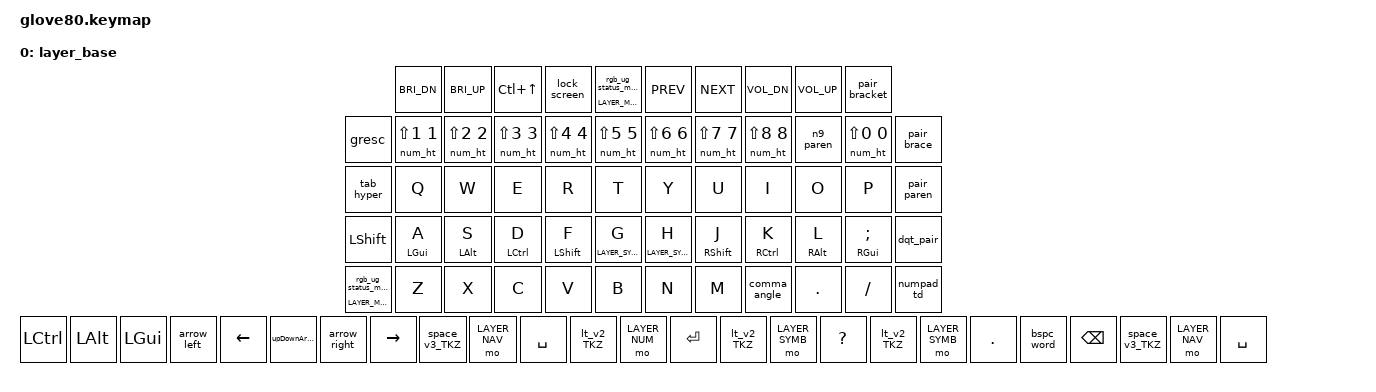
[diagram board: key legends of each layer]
/*
 * Copyright (c) 2020 The ZMK Contributors
 * SPDX-License-Identifier: MIT
 * 
 * Glove80 keymap adapted from sliceMK ErgoDox configuration
 * https://github.com/nothingfortune/unified-zmk-config-template-sliceMK
 */

#include <behaviors.dtsi>
#include <dt-bindings/zmk/keys.h>
#include <dt-bindings/zmk/bt.h>
#include <dt-bindings/zmk/ext_power.h>
#include <dt-bindings/zmk/outputs.h>
#include <dt-bindings/zmk/rgb.h>

/* Mouse speed MUST be defined BEFORE including pointing.h */
#define ZMK_POINTING_DEFAULT_MOVE_VAL 1500  /* default: 600 */
#define ZMK_POINTING_DEFAULT_SCRL_VAL 20    /* default: 10 */

#include <dt-bindings/zmk/pointing.h>

/* Layer definitions */
#define LAYER_BASE 0
#define LAYER_SYMB 1
#define LAYER_PWR 2
#define LAYER_NAV 3
#define LAYER_NMPAD 4
#define LAYER_FN 5
#define LAYER_MAGIC 6

/* Hyper key: Cmd+Ctrl+Alt+Shift - for app launchers like Raycast/Alfred */
#define HYPER LC(LS(LA(LGUI)))

/* Meh key: Ctrl+Alt+Shift (no Cmd) */
#define MEH LC(LS(LALT))

/* Mouse cursor settings - high speed, no acceleration ramp */
&mmv {
    delay-ms = <0>;
    time-to-max-speed-ms = <200>;
    acceleration-exponent = <2>;
};

/* Scroll wheel settings - instant max speed */
&msc {
    delay-ms = <0>;
    time-to-max-speed-ms = <0>;
    acceleration-exponent = <1>;
};

/ {
    behaviors {
        /* Grave/Escape key - Grave when held with Shift/Cmd, Escape otherwise */
        gresc: grave_escape {
            compatible = "zmk,behavior-mod-morph";
            #binding-cells = <0>;
            bindings = <&kp ESC>, <&kp GRAVE>;
            mods = <(MOD_LGUI|MOD_LSFT|MOD_RGUI|MOD_RSFT)>;
        };
        /* N9 key - outputs 9 normally, pair_paren macro when any modifier is held */
        n9_paren: n9_parentheses {
            compatible = "zmk,behavior-mod-morph";
            #binding-cells = <0>;
            bindings = <&kp N9>, <&pair_paren>;
            mods = <(MOD_LSFT|MOD_RSFT|MOD_LCTL|MOD_RCTL|MOD_LALT|MOD_RALT|MOD_LGUI|MOD_RGUI)>;
        };
        /* Comma key - outputs comma normally, pair_angle (<>) when any modifier is held */
        comma_angle: comma_angle_brackets {
            compatible = "zmk,behavior-mod-morph";
            #binding-cells = <0>;
            bindings = <&kp COMMA>, <&pair_angle>;
            mods = <(MOD_LSFT|MOD_RSFT|MOD_LCTL|MOD_RCTL|MOD_LALT|MOD_RALT|MOD_LGUI|MOD_RGUI)>;
        };
        /* Double quote key - outputs " normally, pair_dquote ("") when any modifier is held */
        dqt_pair: double_quote_pair {
            compatible = "zmk,behavior-mod-morph";
            #binding-cells = <0>;
            bindings = <&kp DQT>, <&pair_dquote>;
            mods = <(MOD_LSFT|MOD_RSFT|MOD_LCTL|MOD_RCTL|MOD_LALT|MOD_RALT|MOD_LGUI|MOD_RGUI)>;
        };
        /* Up/Down arrows mod-morph */
        upDownArrows: up_down_arrows {
            compatible = "zmk,behavior-mod-morph";
            #binding-cells = <0>;
            bindings = <&kp DOWN>, <&kp UP>;
            mods = <(MOD_LSFT|MOD_RSFT|MOD_LCTL|MOD_RCTL|MOD_LALT|MOD_RALT|MOD_LGUI|MOD_RGUI)>;
        };

        /* Layer tap for power layer */
        lt_pwr: layer_tap_pwr {
            compatible = "zmk,behavior-hold-tap";
            #binding-cells = <2>;
            flavor = "balanced";
            tapping-term-ms = <280>;
            quick-tap-ms = <175>;
            bindings = <&mo>, <&kp>;
        };

        /* Home row mods - tailored timings from go60 */
        hm: homerow_mod {
            compatible = "zmk,behavior-hold-tap";
            #binding-cells = <2>;
            flavor = "tap-preferred";
            tapping-term-ms = <160>;
            quick-tap-ms = <175>;
            require-prior-idle-ms = <125>;
            bindings = <&kp>, <&kp>;
        };

        /* Home row mods for shift - tailored timings from go60 */
        hms: homerow_mod_shift {
            compatible = "zmk,behavior-hold-tap";
            #binding-cells = <2>;
            flavor = "tap-preferred";
            tapping-term-ms = <160>;
            quick-tap-ms = <175>;
            require-prior-idle-ms = <125>;
            bindings = <&kp>, <&kp>;
        };

        /* Hold backspace = delete word (Option+Backspace on macOS) */
        bspc_word: backspace_word {
            compatible = "zmk,behavior-hold-tap";
            #binding-cells = <2>;
            flavor = "balanced";
            tapping-term-ms = <250>;
            quick-tap-ms = <0>;
            bindings = <&kp>, <&kp>;
        };

        /* Arrow keys with word jump on hold */
        arrow_left: arrow_word_left {
            compatible = "zmk,behavior-hold-tap";
            #binding-cells = <2>;
            flavor = "balanced";
            tapping-term-ms = <200>;
            quick-tap-ms = <150>;
            bindings = <&kp>, <&kp>;
        };

        arrow_right: arrow_word_right {
            compatible = "zmk,behavior-hold-tap";
            #binding-cells = <2>;
            flavor = "balanced";
            tapping-term-ms = <200>;
            quick-tap-ms = <150>;
            bindings = <&kp>, <&kp>;
        };

        /* Magic layer hold-tap for RGB status */
        magic: magic_hold_tap {
            compatible = "zmk,behavior-hold-tap";
            #binding-cells = <2>;
            flavor = "tap-preferred";
            tapping-term-ms = <200>;
            bindings = <&mo>, <&rgb_ug_status_macro>;
        };
    };

    macros {
        rgb_ug_status_macro: rgb_ug_status_macro_0 {
            compatible = "zmk,behavior-macro";
            #binding-cells = <0>;
            bindings = <&rgb_ug RGB_STATUS>;
        };

        bt_0: bt_profile_macro_0 {
            compatible = "zmk,behavior-macro";
            #binding-cells = <0>;
            bindings = <&out OUT_BLE>, <&bt BT_SEL 0>;
        };

        bt_1: bt_profile_macro_1 {
            compatible = "zmk,behavior-macro";
            #binding-cells = <0>;
            bindings = <&out OUT_BLE>, <&bt BT_SEL 1>;
        };

        bt_2: bt_profile_macro_2 {
            compatible = "zmk,behavior-macro";
            #binding-cells = <0>;
            bindings = <&out OUT_BLE>, <&bt BT_SEL 2>;
        };

        bt_3: bt_profile_macro_3 {
            compatible = "zmk,behavior-macro";
            #binding-cells = <0>;
            bindings = <&out OUT_BLE>, <&bt BT_SEL 3>;
        };

        /* Screenshot - ⌘⇧4 (selection) */
        screenshot: screenshot_macro {
            compatible = "zmk,behavior-macro";
            #binding-cells = <0>;
            bindings = <&kp LG(LS(N4))>;
        };

        /* Lock screen - ⌃⌘Q (macOS) */
        lock_screen: lock_screen_macro {
            compatible = "zmk,behavior-macro";
            #binding-cells = <0>;
            bindings = <&kp LC(LG(Q))>;
        };

        /* Screenshot to clipboard - ⌘⌃⇧4 */
        screenshot_clip: screenshot_clipboard_macro {
            compatible = "zmk,behavior-macro";
            #binding-cells = <0>;
            bindings = <&kp LG(LC(LS(N4)))>;
        };

        /* Rectangle: Left Half - ⌃⌥← */
        rect_left: rectangle_left_half {
            compatible = "zmk,behavior-macro";
            #binding-cells = <0>;
            bindings = <&kp LC(LA(LEFT))>;
        };

        /* Rectangle: Right Half - ⌃⌥→ */
        rect_right: rectangle_right_half {
            compatible = "zmk,behavior-macro";
            #binding-cells = <0>;
            bindings = <&kp LC(LA(RIGHT))>;
        };

        /* Rectangle: Maximize - ⌃⌥↩ */
        rect_max: rectangle_maximize {
            compatible = "zmk,behavior-macro";
            #binding-cells = <0>;
            bindings = <&kp LC(LA(RET))>;
        };

        /* Rectangle: Top Half - ⌃⌥↑ */
        rect_top: rectangle_top_half {
            compatible = "zmk,behavior-macro";
            #binding-cells = <0>;
            bindings = <&kp LC(LA(UP))>;
        };

        /* Rectangle: Bottom Half - ⌃⌥↓ */
        rect_bottom: rectangle_bottom_half {
            compatible = "zmk,behavior-macro";
            #binding-cells = <0>;
            bindings = <&kp LC(LA(DOWN))>;
        };

        /* Hyper key macro - ⌘⌃⌥⇧ for Raycast/Alfred */
        hyper_key: hyper_key_macro {
            compatible = "zmk,behavior-macro";
            #binding-cells = <0>;
            bindings = <&sk LGUI>, <&sk LALT>, <&sk LCTRL>, <&sk LSHFT>;
        };
        
        /* Auto-pair macros - type opening + closing, cursor moves to middle */
        pair_paren: pair_parentheses {
            compatible = "zmk,behavior-macro";
            #binding-cells = <0>;
            bindings = <&kp LPAR>, <&kp RPAR>, <&kp LEFT>;
        };

        pair_bracket: pair_brackets {
            compatible = "zmk,behavior-macro";
            #binding-cells = <0>;
            bindings = <&kp LBKT>, <&kp RBKT>, <&kp LEFT>;
        };

        pair_brace: pair_braces {
            compatible = "zmk,behavior-macro";
            #binding-cells = <0>;
            bindings = <&kp LBRC>, <&kp RBRC>, <&kp LEFT>;
        };

        pair_angle: pair_angle_brackets {
            compatible = "zmk,behavior-macro";
            #binding-cells = <0>;
            bindings = <&kp LT>, <&kp GT>, <&kp LEFT>;
        };

        pair_dquote: pair_double_quotes {
            compatible = "zmk,behavior-macro";
            #binding-cells = <0>;
            bindings = <&kp DQT>, <&kp DQT>, <&kp LEFT>;
        };

        pair_squote: pair_single_quotes {
            compatible = "zmk,behavior-macro";
            #binding-cells = <0>;
            bindings = <&kp SQT>, <&kp SQT>, <&kp LEFT>;
        };

        pair_backtick: pair_backticks {
            compatible = "zmk,behavior-macro";
            #binding-cells = <0>;
            bindings = <&kp GRAVE>, <&kp GRAVE>, <&kp LEFT>;
        };

    };

    keymap {
        compatible = "zmk,keymap";

        /* LAYER 0: Base Layer - QWERTY with Home Row Mods (matched to go60 as close as possible) */
        layer_base {
            bindings = <
            /* Row 0: Function row */
            &kp C_BRI_DN &kp C_BRI_UP &kp LC(UP) &lock_screen &magic LAYER_MAGIC 0 &kp C_PREV &kp C_NEXT &kp C_VOL_DN &kp C_VOL_UP &pair_bracket
            /* Row 1: Number row */
            &gresc &num_ht LS(N1) N1 &num_ht LS(N2) N2 &num_ht LS(N3) N3 &num_ht LS(N4) N4 &num_ht LS(N5) N5 &num_ht LS(N6) N6 &num_ht LS(N7) N7 &num_ht LS(N8) N8 &n9_paren &num_ht LS(N0) N0 &pair_brace
            /* Row 2: Top alpha row */
            &tab_hyper &kp Q &kp W &kp E &kp R &kp T &kp Y &kp U &kp I &kp O &kp P &pair_paren
            /* Row 3: Home row with mods */
            &kp LSHFT &hm LGUI A &hm LALT S &hm LCTRL D &hms LSHFT F &lt LAYER_SYMB G &lt LAYER_SYMB H &hms RSHFT J &hm RCTRL K &hm RALT L &hm RGUI SEMI &dqt_pair
            /* Row 4: Bottom alpha + inner keys */
            &magic LAYER_MAGIC 0 &kp Z &kp X &kp C &kp V &kp B &kp N &kp M &comma_angle &kp DOT &kp FSLH &numpad_td
            /* Row 5: Thumb cluster */
            &kp LCTRL &kp LALT &kp LGUI &arrow_left &kp LEFT &upDownArrows &arrow_right &kp RIGHT &space_v3_TKZ &mo LAYER_NAV &kp SPACE &lt_v2_TKZ &mo LAYER_NUM &kp RET &lt_v2_TKZ &mo LAYER_SYMB &kp QMARK &lt_v2_TKZ &mo LAYER_SYMB &kp PERIOD &bspc_word &kp BSPC &space_v3_TKZ &mo LAYER_NAV &kp SPACE
            >;
        }
        };

        /* LAYER 1: Symbol Layer - matches sliceMK ErgoDox layout */
        layer_symb {
            bindings = <
            /* Row 0: Function row */
            &none               &none        &none        &none        &none                                                                                                       &none        &none        &none        &none           &trans
            /* Row 1: ~ on left, ` and trans on right */
            &none               &none    &none        &none        &none        &none                                                                               &none      &none        &none        &none        &none       &trans
            /* Row 2: _ $ # ^ on left (QWER), _ @ % on right (UIO) */
            &none               &kp TILDE        &kp DLLR     &kp HASH     &kp CARET    &none                                                                               &none      &kp UNDER    &kp AT       &kp PRCNT    &kp GRAVE           &trans
            /* Row 3: - * | & on left (ASDF), ( ) + = : on right (JKL;') */
            &none               &kp MINUS    &kp ASTRK    &kp PIPE     &kp AMPS     &none                                                                               &none      &pair_paren     &kp RPAR     &kp PLUS     &kp EQUAL       &kp COLON
            /* Row 4: { } < > on left (ZXCV), [ ] ! ? on right (M,./) */
            &none               &pair_brace     &kp RBRC     &kp LT       &kp GT       &none      &none        &none        &none         &none         &none         &none          &none      &pair_bracket     &kp RBKT     &kp EXCL     &kp QMARK       &trans
            /* Row 5: Thumb cluster - transparent */
            &trans              &trans       &trans       &trans       &trans                 &trans       &trans       &none         &none         &trans        &trans                    &trans       &trans       &trans       &trans          &none
            >;
        };

        /* LAYER 2: Power/Shortcuts Layer */
        layer_pwr {
            bindings = <
            &none               &none        &none        &none        &none                                                                                                       &none        &none        &none        &none           &none
            &none               &kp LC(Z)    &kp LC(LS(Z)) &kp LC(LS(N4)) &none     &none                                                                               &none      &none        &none        &none        &none           &kp LC(BSPC)
            &none               &kp LC(A)    &kp LS(TAB)  &kp TAB      &none        &none                                                                               &none      &kp LC(LEFT) &kp UP       &kp LC(RIGHT) &kp PG_UP      &kp LC(DEL)
            &none               &sk LCTRL    &sk LSHFT    &sk LALT     &sk LGUI     &sk LC(LS(LA(LGUI)))                                                                &none      &kp LEFT     &kp DOWN     &kp RIGHT    &kp PG_DN       &none
            &none               &kp LC(X)    &kp LC(C)    &kp LC(V)    &none        &none      &none        &none        &none         &none         &none         &none          &none      &kp HOME     &none        &kp END      &none           &none
            &none               &none        &none        &trans       &trans                 &none        &none        &none         &none         &none         &none                     &kp LS(LA(LEFT)) &trans   &trans       &kp LS(LA(RIGHT)) &none
            >;
        };

        /* LAYER 3: Navigation/Mouse Layer */
        layer_nav {
            bindings = <
            &none               &none        &none        &none        &none                                                                                                       &none        &none        &none        &none           &none
            &none               &none        &msc SCRL_UP &none        &mkp RCLK    &none                                                                               &none      &mkp RCLK    &none        &msc SCRL_UP &none           &none
            &none               &none        &msc SCRL_DOWN &mmv MOVE_UP &mkp LCLK  &none                                                                               &none      &mkp LCLK    &mmv MOVE_UP &msc SCRL_DOWN &none        &none
            &none               &none        &mmv MOVE_LEFT &mmv MOVE_DOWN &mmv MOVE_RIGHT &none                                                                        &none      &mmv MOVE_LEFT &mmv MOVE_DOWN &mmv MOVE_RIGHT &none   &none
            &none               &none        &none        &none        &none        &none      &none        &none        &none         &none         &none         &none          &none      &none        &none        &none        &none           &none
            &none               &none        &none        &mkp LCLK    &mkp RCLK              &none        &none        &none         &none         &none         &none                     &trans       &trans       &trans       &trans          &none
            >;
        };

        /* LAYER 4: Numpad Layer */
        layer_nmpad {
            bindings = <
            &none               &kp F1       &kp F2       &kp F3       &kp F4                                                                                                      &kp F7       &kp F8       &kp F9       &kp F10         &none
            &none               &kp F5       &kp F6       &none        &none        &none                                                                               &none      &kp F11      &kp F12      &none        &none           &trans
            &kp TAB             &kp FSLH     &kp N7       &kp N8       &kp N9       &kp ASTRK                                                                           &none      &kp FSLH     &kp N7       &kp N8       &kp N9          &kp ASTRK
            &none               &kp MINUS    &kp N4       &kp N5       &kp N6       &kp PLUS                                                                            &none      &kp MINUS    &kp N4       &kp N5       &kp N6          &kp PLUS
            &none               &none        &kp N1       &kp N2       &kp N3       &kp EQUAL  &kp C_BRI_DN &kp C_BRI_UP &none         &none         &none         &none          &none      &none        &kp N1       &kp N2       &kp N3          &kp EQUAL
            &none               &none        &kp DOT      &kp N0       &kp COMMA              &none        &none        &none         &none         &none         &none                     &kp DOT      &kp N0       &kp COMMA    &none           &trans
            >;
        };

        /* LAYER 5: Function/System Layer */
        layer_fn {
            bindings = <
            &bt BT_SEL 0        &bt BT_SEL 1 &bt BT_SEL 2 &bt BT_SEL 3 &bt BT_SEL 4                                                                                                &none        &none        &none        &none           &bt BT_CLR
            &out OUT_USB        &kp F1       &kp F2       &kp F3       &kp F4       &none                                                                               &none      &kp F13      &kp F14      &kp F15      &kp F16         &none
            &out OUT_BLE        &kp F5       &kp F6       &kp F7       &kp F8       &none                                                                               &none      &kp F17      &kp F18      &kp F19      &kp F20         &none
            &none               &kp F9       &kp F10      &kp F11      &kp F12      &none                                                                               &none      &kp F21      &kp F22      &kp F23      &kp F24         &none
            &none               &none        &none        &none        &none        &none      &none        &none        &none         &none         &none         &none          &none      &none        &none        &none        &none           &bt BT_CLR
            &bootloader         &none        &none        &none        &none                   &none        &none        &none         &none         &none         &none                     &none        &none        &none        &none           &bootloader
            >;
        };

        /* LAYER 6: Magic Layer (Glove80 specific) */
        layer_magic {
            bindings = <
            &bt BT_CLR          &none        &none        &none        &none                                                                                                       &none        &none        &none        &none           &bt BT_CLR_ALL
            &none               &none        &none        &none        &none        &none                                                                               &none      &none        &none        &none        &none           &none
            &none               &rgb_ug RGB_SPI &rgb_ug RGB_SAI &rgb_ug RGB_HUI &rgb_ug RGB_BRI &rgb_ug RGB_TOG                                                         &none      &none        &none        &none        &none           &none
            &bootloader         &rgb_ug RGB_SPD &rgb_ug RGB_SAD &rgb_ug RGB_HUD &rgb_ug RGB_BRD &rgb_ug RGB_EFF                                                         &none      &none        &none        &none        &none           &bootloader
            &sys_reset          &none        &none        &none        &none        &none      &bt_2        &bt_3        &none         &none         &none         &none          &none      &none        &none        &none        &none           &sys_reset
            &none               &none        &none        &none        &none                   &bt_0        &bt_1        &out OUT_USB  &none         &none         &none                     &none        &none        &none        &none           &none
            >;
        };
    };
};
